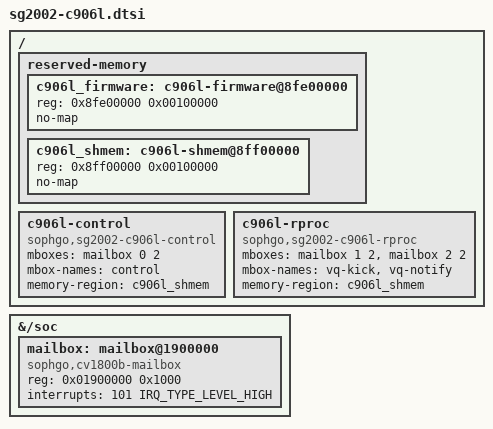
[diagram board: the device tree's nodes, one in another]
/* SPDX-License-Identifier: (GPL-2.0 OR MIT) */
/*
 * Memory and doorbell resources for firmware started by the SG2002 FSBL on
 * the C906L.  Keep this fragment opt-in: a FIP without C906L firmware must
 * continue to expose the complete 256 MiB to Linux.
 */

/ {
	reserved-memory {
		#address-cells = <1>;
		#size-cells = <1>;
		ranges;

		c906l_firmware: c906l-firmware@8fe00000 {
			reg = <0x8fe00000 0x00100000>;
			no-map;
		};

		c906l_shmem: c906l-shmem@8ff00000 {
			reg = <0x8ff00000 0x00100000>;
			no-map;
		};
	};

	c906l-control {
		compatible = "sophgo,sg2002-c906l-control";
		mboxes = <&mailbox 0 2>;
		mbox-names = "control";
		memory-region = <&c906l_shmem>;
	};

	c906l-rproc {
		compatible = "sophgo,sg2002-c906l-rproc";
		/* Separate slots prevent bidirectional doorbell overwrite. */
		mboxes = <&mailbox 1 2>, <&mailbox 2 2>;
		mbox-names = "vq-kick", "vq-notify";
		memory-region = <&c906l_shmem>;
	};
};

&{/soc} {
	mailbox: mailbox@1900000 {
		compatible = "sophgo,cv1800b-mailbox";
		reg = <0x01900000 0x1000>;
		interrupts = <101 IRQ_TYPE_LEVEL_HIGH>;
		#mbox-cells = <2>;
	};
};
